# TC37XPD register map
Vendor: Infineon; Series: ATVMC; File version: 100
CPU: other r0p0, little endian, MPU, FPU, vendor SysTick, 4 interrupt priority bits
Registers are 32-bit, read-write, reset 0x0 unless marked. A register's access mark holds for its fields unless they carry their own. Offsets are from the block's base; [hi:lo] are bit positions; lines under a group give offsets from that group; {n}, {i} and the like mark numbered series.

## EDSADC
Base 0xF0024000
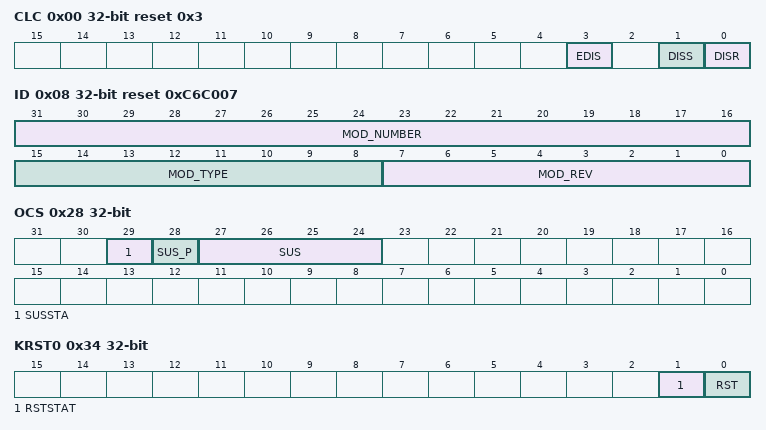
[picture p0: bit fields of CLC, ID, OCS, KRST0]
0x00 CLC access per field reset 0x3 — Clock Control Register resetvalue={Application Reset:0x3}
  [3] EDIS rw — Sleep Mode Enable Control EDIS. Used to control the module 8217 s reaction to sleep mode.
  [1] DISS ro — Module Disable Status Bit DISS
  [0] DISR rw — Module Disable Request Bit DISR. Used for enable disable control of the module.
0x08 ID ro reset 0xC6C007 — Module Identification Register resetvalue={PowerOn Reset:0x0C6C007}
  [31:16] MOD_NUMBER — Module Number MOD NUMBER. Indicates the module identification number 00C6 EDSADC
  [15:8] MOD_TYPE — Module Type MOD TYPE. This internal marker is fixed to C0 .
  [7:0] MOD_REV — Module Revision MOD REV. Indicates the revision number of the implementation. This information depends on the design step.
0x28 OCS access per field — OCDS Control and Status Register resetvalue={PowerOn Reset:0x0,Debug Reset:0x0}
  [29] SUSSTA ro — Suspend State SUSSTA
  [28] SUS_P wo — SUS Write Protection SUS P. SUS is only written when SUS P is 1 otherwise unchanged. Read as 0.
  [27:24] SUS rw — OCDS Suspend Control SUS. Controls the sensitivity to the suspend signal coming from the OCDS Trigger Switch OTGS . In soft suspend mode the respective channel is stopped after the next result has been stored. For products with less channels the upper codes are reserved.
0x2C KRSTCLR wo — Kernel Reset Status Clear Register resetvalue={Application Reset:0x0}
  [0] CLR — Kernel Reset Status Clear CLR. Read always as 0.
0x30 KRST1 — Kernel Reset Register 1 resetvalue={Application Reset:0x0}
  [0] RST — Kernel Reset RST. Request a kernel reset. The reset is executed if the reset bits of both kernel reset registers are set. RST is cleared after the kernel reset was executed.
0x34 KRST0 access per field — Kernel Reset Register 0 resetvalue={Application Reset:0x0}
  [1] RSTSTAT ro — Kernel Reset Status RSTSTAT. Indicates an executed kernel reset. RSTSTAT is set after the execution of a kernel reset in the same clock cycle in which the reset bits are cleared. Clear RSTSTAT by setting bit CLR in register KRSTCLR.
  [0] RST rw — Kernel Reset RST. Request a kernel reset. The reset is executed if the reset bits of both kernel reset registers are set. RST is cleared after the kernel reset was executed.
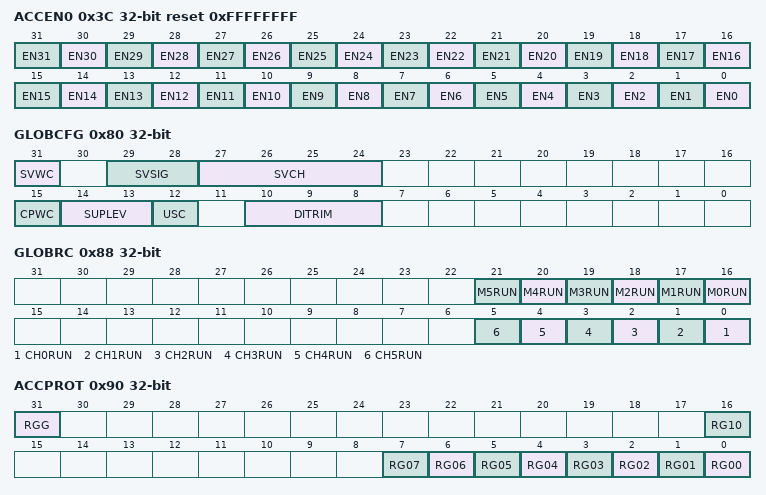
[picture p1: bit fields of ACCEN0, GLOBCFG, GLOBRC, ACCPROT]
0x3C ACCEN0 reset 0xFFFFFFFF — Access Enable Register 0 resetvalue={Application Reset:0x0FFFFFFFF}
  [n] EN{n} (n=0..31) — Access Enable for Master TAG ID 31 EN31. This bit enables write access to the module kernel addresses for transactions with the Master TAG ID n
0x80 GLOBCFG access per field — Global Configuration Register resetvalue={Application Reset:0x0}
  [31] SVWC wo — Write Control for Supervision Parameters
  [29:28] SVSIG rw — Supervision Signal Select. Defines the supervision signal of the channel selected by SVCH to be output.
  [27:24] SVCH rw — Supervision Channel Select. Defines the channel for which the supervision signal selected by SVSIG is output. Not listed combinations are reserved.
  [15] CPWC wo — Write Control for Clock Parameters CPWC
  [14:13] SUPLEV rw — Supply Voltage Level. Adjusts the analog circuitry to the supply voltage used in the application system. Make sure to keep SUPLEV 00 B or 01 B in the case of a 5 V supply.
  [12] USC rw — Unsynchronized Clock Generation USC. Defines the way the modulator clock is generated.
  [10:8] DITRIM rw — Trimming Value for the Dithering Function DITRIM. This trim value is used for all modulators of the device. Not listed combinations are reserved.
0x88 GLOBRC — Global Run Control Register resetvalue={Application Reset:0x0}
  [n+16] M{n}RUN (n=0..5) — Modulator 5 Run Control M5RUN. Each bit when set enables the corresponding modulator.
  [n] CH{n}RUN (n=0..5) — Channel 5 Run Control CH5RUN. Each bit when set enables the corresponding demodulator channel. When CHxRUN is set all filter blocks are cleared and the FIFO is flushed.
0x90 ACCPROT — Access Protection Register resetvalue={Application Reset:0x0}
  [31] RGG — Register Group Global RGG
  [16] RG10 — Register Group 10 RG10
  [n] RG{n:02} (n=0..7) — Register Group 7 RG07
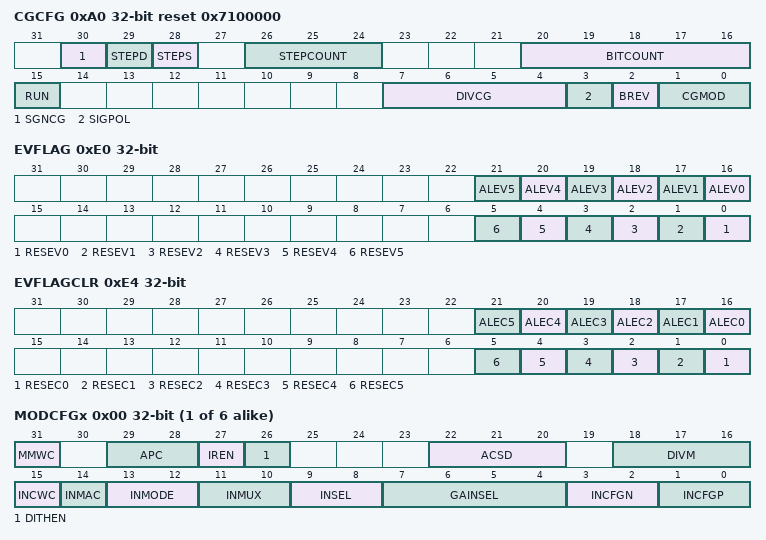
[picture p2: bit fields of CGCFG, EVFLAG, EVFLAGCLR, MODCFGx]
0xA0 CGCFG access per field reset 0x7100000 — Carrier Generator Configuration Register resetvalue={Application Reset:0x7100000}
  [30] SGNCG ro — Sign Signal from Carrier Generator SGNCG
  [29] STEPD ro — Step Counter Direction STEPD
  [28] STEPS ro — Step Counter Sign STEPS. Indicates the sign of the step counter value
  [26:24] STEPCOUNT ro — Step Counter STEPCOUNT. Counts the 8 steps generated for each quadrant of the carrier signal period
  [20:16] BITCOUNT ro — Bit Counter BITCOUNT. Counts the 32 cycles generated for each step
  [15] RUN ro — Run Indicator RUN
  [7:4] DIVCG rw — Divider Factor for the PWM Pattern Signal Generator DIVCG. Defines the input frequency of the carrier signal generator derived from the selected internal clock source f CG f ADC CGP. The frequency of the carrier signal itself is f CG 1024.
  [3] SIGPOL rw — Signal Polarity SIGPOL
  [2] BREV rw — Bit Reverse PWM Generation BREV
  [1:0] CGMOD rw — Carrier Generator Operating Mode CGMOD. Stopping the carrier generator CGMOD 160 160 00 terminates the PWM output after completion of the current period indicated by bit RUN 160 160 0 .
0xE0 EVFLAG — Event Flag Register resetvalue={Application Reset:0x0}
  [n+16] ALEV{n} (n=0..5) — Alarm Event ALEV5
  [n] RESEV{n} (n=0..5) — Result Event RESEV5. Bit RESEVx is cleared when result register RESMx is read or when bit RESECx is written with 1.
0xE4 EVFLAGCLR wo — Event Flag Clear Register resetvalue={Application Reset:0x0}
  [n+16] ALEC{n} (n=0..5) — Alarm Event Clear ALEC5
  [n] RESEC{n} (n=0..5) — Result Event Clear RESEC5
{0x100+0x100*i} CH[{i}] (i=0..5) group
  0x00 MODCFGx access per field — Modulator Configuration Register 0 resetvalue={Application Reset:0x0}
    [31] MMWC wo — Write Control for Modulator Mode Settings MMWC
    [29:28] APC rw — Automatic Power Control APC
    [27] IREN rw — Integrator Reset Enable IREN. Controls the modulator overdrive handling
    [26] DITHEN rw — Dithering Function Enable DITHEN. Controls the dithering function for each modulator separately.
    [22:20] ACSD rw — Analog Clock Synchronization Delay ACSD. Defines the delay in clocks after the sync signal. Valid only if the phase synchronizer is selected USC 160 160 0 .
    [18:16] DIVM rw — Modulator Clock Period DIVM. Defines the period of the modulator clock on chip external derived from the peripheral clock t MOD t ADC xd7 CP f MOD f ADC CP with CP 4 DIVM xd7 2.
    [15] INCWC wo — Write Control for Input Parameters INCWC
    [14] INMAC rw — Input Multiplexer Action Control INMAC. Defines the mechanism by which the input multiplexer is controlled.
    [13:12] INMODE rw — Input Multiplexer Control Mode INMODE. Defines the condition for a trigger event to control the input multiplexer. Bitfield INMAC selects the action upon a trigger event.
    [11:10] INMUX ro — Input Multiplexer Setting INMUX. Indicates the current setting of the input multiplexer connecting the input pins to the buffer inputs. The product specific appendix details the available channels and their inputs.
    [9:8] INSEL rw — Input Pin Selection INSEL. Defines the initial or permanent setting for the input multiplexer bitfield INMUX depending on the selected operating mode bitfield INMODE .
    [7:4] GAINSEL rw — Gain Select of Analog Input Path GAINSEL. Not listed combinations are reserved.
    [3:2] INCFGN rw — Configuration of Negative Input Line INCFGN. Defines the internal connection of the negative input.
    [1:0] INCFGP rw — Configuration of Positive Input Line INCFGP. Defines the internal connection of the positive input.
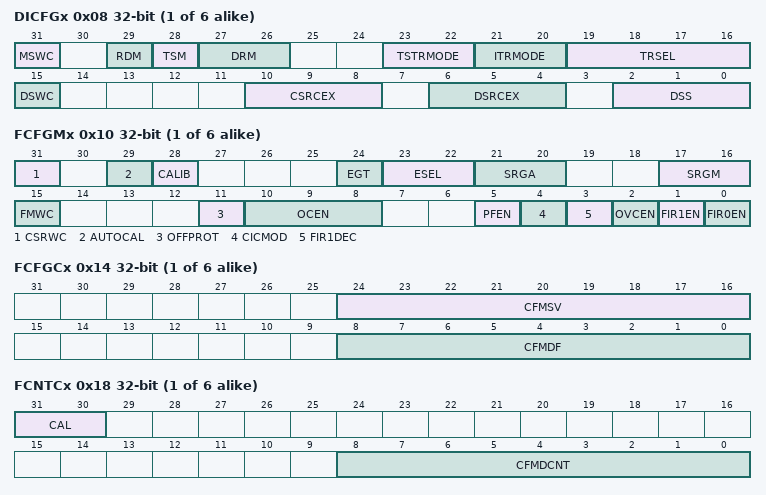
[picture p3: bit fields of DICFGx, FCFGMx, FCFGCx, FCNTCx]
  0x08 DICFGx access per field — Demodulator Input Config. Register 0 resetvalue={Application Reset:0x0}
    [31] MSWC wo — Write Control for Mode Settings MSWC
    [29] RDM rw — Result Display Mode RDM
    [28] TSM rw — Time Stamp Mode TSM. See CROSSREFERENCE .
    [27:26] DRM rw — Data Read Mode DRM. Selects the data that is returned when register RESMx is read see CROSSREFERENCE .
    [23:22] TSTRMODE rw — Timestamp Trigger Mode TSTRMODE. The timestamp trigger mode controls capturing the timestamp information to register TSTMPx .
    [21:20] ITRMODE rw — Integrator Trigger Mode ITRMODE. To ensure proper operation ensure that bitfield ITRMODE is 00 before selecting any other trigger mode. The integration trigger mode controls bit INTEN in register IWCTRx and hence the operation of the integrator Bit INTEN is set when ITRMODE 160 160 11 or when the selected trigger signal transition occurs. Bit INTEN is cleared when ITRMODE 160 160 00 after REPVAL 1 integration cycles IWS 160 160 0 or when the inverse trigger signal transition occurs IWS 160 160 1 .
    [19:16] TRSEL rw — Trigger Select TRSEL. Selects an input for the trigger signal used for the following features see also CROSSREFERENCE To avoid unintended triggers select the trigger source first before enabling the corresponding function. integrator control timestamp multiplexer control modulator control APC service request gating. The product specific appendix details the connected trigger input signals.
    [15] DSWC wo — Write Control for Data Stream Selection DSWC
    [10:8] CSRCEX rw — Clock Source for External Modulator CSRCEX
    [6:4] DSRCEX rw — Data Source for External Modulator DSRCEX
    [2:0] DSS rw — Data Stream Select DSS
  0x10 FCFGMx access per field — Filter Configuration Register 0 Main resetvalue={Application Reset:0x0}
    [31] CSRWC wo — Write Control for Calibration and Service Request Modes CSRWC
    [29] AUTOCAL rw — Automatic Calibration Control AUTOCAL
    [28] CALIB wo — Calibration Trigger CALIB
    [24] EGT rw — Event Gating. Defines if alarm events are coupled to the integration window.
    [23:22] ESEL rw — Event Select ESEL. Defines when a comparator event is generated.
    [21:20] SRGA rw — Service Request Generation for Alternate Service Request SRGA. SRGA 160 160 00 can be used for testing If TEST.ICTEN 160 160 1 Reload request for test shift register
    [17:16] SRGM rw — Service Request Generation for Main Service Request SRGM
    [15] FMWC wo — Write Control for Filter Modes FMWC
    [11] OFFPROT rw — Offset Protection OFFPROT. Controls the influence of the calibration sequence on register OFFCOMP.
    [10:8] OCEN rw — Offset Compensation Filter Enable OCEN
    [5] PFEN rw — Prefilter Enable PFEN
    [4] CICMOD rw — CIC Filter Mode CICMOD
    [3] FIR1DEC rw — FIR1 Filter Decimation Rate FIR1DEC
    [2] OVCEN rw — Overshoot Compensation Enable
    [1] FIR1EN rw — FIR1 Filter Enable FIR1EN
    [0] FIR0EN rw — FIR0 Filter Enable FIR0EN
  0x14 FCFGCx — Filter Configuration Register 0 CIC Filter resetvalue={Application Reset:0x0}
    [24:16] CFMSV — CIC Filter Start Value CFMSV. The decimation counter begins counting at value CFMSV when started or restarted. Valid values are 003 to CFMDF 4 to selected OSR . Start values above the selected oversampling rate may lead to overflows in the CIC filter
    [8:0] CFMDF — CIC Filter Decimation Factor CFMDF. Defines the oversampling rate of the CIC filter OSR CFMDF 160 160 1. Valid values are 0 03 to 1FF OSR 4 to 512 .
  0x18 FCNTCx ro — Filter Counter Register 0 CIC Filter resetvalue={Application Reset:0x0}
    [31:30] CAL — Calibration Status Flag CAL. Bitfield CAL is set to 01 in the next clock cycle after setting bit CALIB or after detecting the selected trigger if auto calibration is activated .
    [8:0] CFMDCNT — CIC Filter Decimation Counter CFMDCNT. The decimation counter counts the filter cycles until an output is generated i.e. the oversampling rate. CFMDCNT counts down from the respective start value.
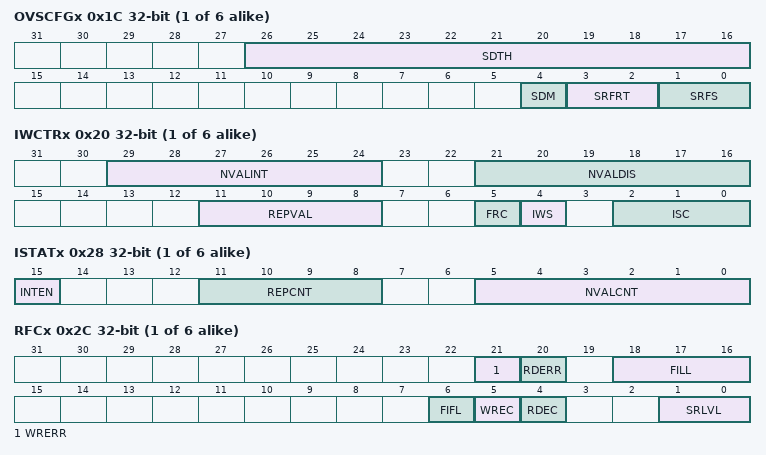
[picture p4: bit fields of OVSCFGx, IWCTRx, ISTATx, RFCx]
  0x1C OVSCFGx — Overshoot Compensation Cfg. Register 0 resetvalue={Application Reset:0x0}
    [26:16] SDTH — Step Detection Threshold. Defines the threshold value magnitude used for step detection. The threshold value is lt SDTH gt 215 32
    [4] SDM — Step Detection Mode. Defines when the slew rate filter is activated.
    [3:2] SRFRT — Slew Rate Filter Run Time. Defines the time constant for the slew rate filter.
    [1:0] SRFS — Slew Rate Filter Strength. Defines the time constant for the slew rate filter.
  0x20 IWCTRx — Integration Window Control Register 0 resetvalue={Application Reset:0x0}
    [29:24] NVALINT — Number of Values to be Accumulated NVALINT. Stop the integration cycle after NVALINT 1 values Use intervals of 2 minimum so no data is lost due to the data shifter.
    [21:16] NVALDIS — Number of Values Discarded NVALDIS. Start the integration cycle after NVALDIS values
    [11:8] REPVAL — Number of Integration Cycles REPVAL. Defines the number of integration cycles to be counted by REPCNT if activated IWS 160 160 0 . The number of cycles is REPVAL 1.
    [5] FRC — Filter Chain Restart Control
    [4] IWS — Integration Window Size IWS
    [2:0] ISC — Integrator Shift Control ISC. Controls the data shifter after the integrator that selects the portion of the integrator data for the result register. 110 8230 111 are reserved. ISC selects the respective bits in register IIVAL. The lowest selected bit is used for rounding and is then removed.
  0x24 IIVALx ro — Intermediate Integration Value resetvalue={Application Reset:0x0}
    [25:0] IVAL — Result of most recent accumulation IVAL
  0x28 ISTATx ro — Integrator Status Register 0 resetvalue={Application Reset:0x0}
    [15] INTEN — Integration Enable INTEN. Indicates the activity of the integrator. For the control of bit INTEN see also bitfield ITRMODE in register DICFGx .
    [11:8] REPCNT — Integration Cycle Counter REPCNT. Counts the number of integration cycles if activated IWS 160 160 0 . This number is selected via bitfield REPVAL.
    [5:0] NVALCNT — Number of Values Counted NVALCNT. Counts the number of integrated values until integration is started NVALDIS or completed NVALINT
  0x2C RFCx access per field — Result FIFO Control Register 0 resetvalue={Application Reset:0x0}
    [21] WRERR ro — Write Error Flag
    [20] RDERR ro — Read Error Flag
    [18:16] FILL ro — FIFO Fill Level. Not listed combinations are reserved.
    [6] FIFL wo — FIFO Flush
    [5] WREC wo — Write Error Flag Clear
    [4] RDEC wo — Read Error Flag Clear
    [1:0] SRLVL rw — Service Request FIFO Level
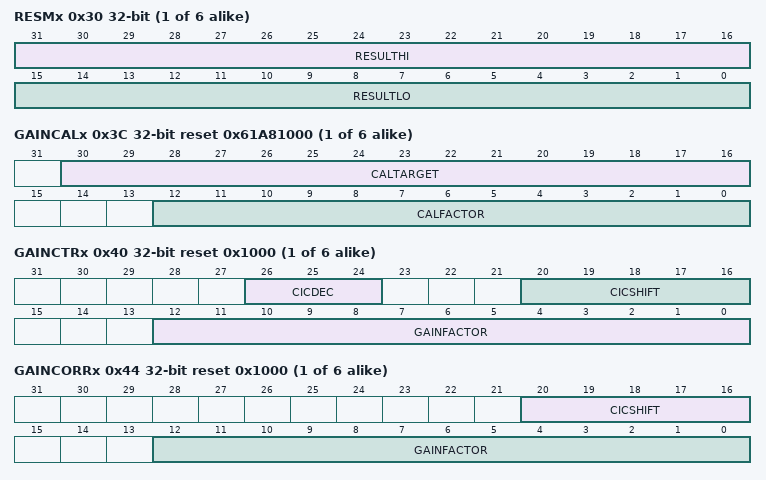
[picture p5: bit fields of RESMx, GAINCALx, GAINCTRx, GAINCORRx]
  0x30 RESMx ro — Result Register 0 Main resetvalue={Application Reset:0x0}
    [31:16] RESULTHI — Result Value Higher Part RESULTHI. Returns an additional value Sign extension result from FIFO timestamp or zero see CROSSREFERENCE
    [15:0] RESULTLO — Result Value Lower Part RESULTLO. Returns the next value from the result FIFO Result or timestamp see CROSSREFERENCE
  0x38 OFFCOMPx — Offset Compensation Register 0 resetvalue={Application Reset:0x0}
    [15:0] OFFSET — Offset Value OFFSET. Half of this signed value is subtracted from each result produced by the filter chain. Bit 0 represents 1 2 LSB. This increases the precision in case of accumulated result values e.g. in the integrator.
  0x3C GAINCALx reset 0x61A81000 — Gain Calibration Register 0 resetvalue={Application Reset:0x61A81000}
    [30:16] CALTARGET — Target Value for Calibrated Fullscale CALTARGET. Defines the target value for the calibration algorithm. The initial value of 25 160 000 61A8 corresponds to 0.2 160 mV per LSB.
    [12:0] CALFACTOR — Multiplication Factor for Gain Calibration CALFACTOR. The resulting factor is lt CALFACTOR gt 4 160 096 The initial value of 4 160 096 1000 corresponds to a factor of 1.000.
  0x40 GAINCTRx reset 0x1000 — Gain Control Register 0 resetvalue={Application Reset:0x1000}
    [26:24] CICDEC — Decimation Rate of the CIC Filter During Calibration CICDEC. Factor 2 CICDEC 3
    [20:16] CICSHIFT — Position of the CIC Filter Output Shifter During Calibration CICSHIFT. Selects the valid outputs bits from the CIC filter depending on the chosen decimation factor see data shifter formula 1D x2026 1F are reserved.
    [12:0] GAINFACTOR — Multiplication Factor for Gain Correction During Calibration GAINFACTOR. The resulting factor is lt GAINFACTOR gt 4 160 096
  0x44 GAINCORRx reset 0x1000 — Gain Correction Register 0 resetvalue={Application Reset:0x1000}
    [20:16] CICSHIFT — Position of the CIC Filter Output Shifter. Selects the valid outputs bits from the CIC filter depending on the chosen decimation factor see formula above 1D 8230 1F are reserved.
    [12:0] GAINFACTOR — Multiplication Factor for Gain Correction GAINFACTOR. The resulting factor is lt GAINFACTOR gt 4 160 096
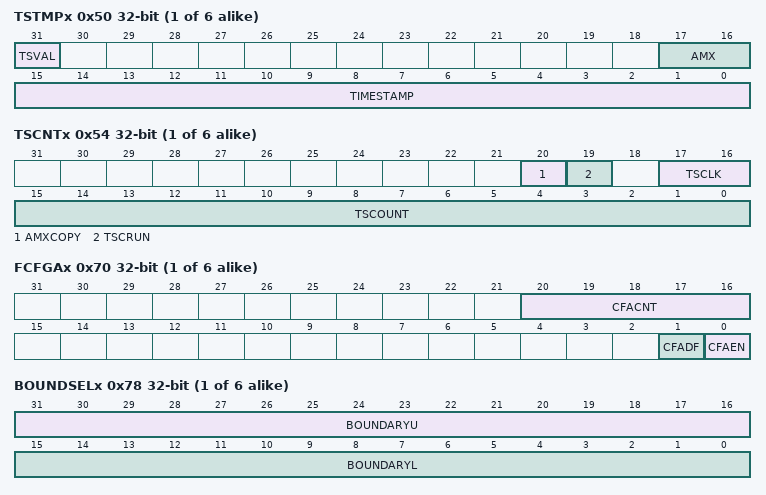
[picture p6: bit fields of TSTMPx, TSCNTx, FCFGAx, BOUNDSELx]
  0x50 TSTMPx ro — Time Stamp Register 0 resetvalue={Application Reset:0x0}
    [31] TSVAL — Timestamp Valid TSVAL. Indicates valid timestamp information.
    [17:16] AMX — Analog Multiplexer Setting AMX. This value is copied from bitfield INMUX in register MODCFGx
    [15:0] TIMESTAMP — The Most Recent Captured Timestamp Value TIMESTAMP. This value is copied from the timestamp counter TSCOUNT If bit AMXCOPY in register TSCNTx is 1 bits TIMESTAMP 15 14 are replaced with a copy of bitfield AMX.
  0x54 TSCNTx access per field — Time Stamp Counter 0 resetvalue={Application Reset:0x0}
    [20] AMXCOPY rw — Analog MUX Setting Copy Enable AMXCOPY. Allows copying of bitfield AMX into bitfield TIMESTAMP in register TSTMPx .
    [19] TSCRUN rw — Timestamp Counter Run Control TSCRUN
    [17:16] TSCLK rw — Timestamp Counter Clock Selection TSCLK
    [15:0] TSCOUNT ro — Timestamp Counter Value TSCOUNT. TSCOUNT is clocked with the modulator clock and is cleared when a new result value has been generated.
  0x70 FCFGAx access per field — Auxiliary Filter Configuration Register 0 resetvalue={Application Reset:0x0}
    [20:16] CFACNT ro — CIC Filter Auxiliary Decimation Counter. The decimation counter counts the filter cycles until an output is generated i.e. the oversampling rate.
    [1] CFADF rw — CIC Filter Auxiliary Decimation Factor
    [0] CFAEN rw — CIC Filter Auxiliary Enable
  0x78 BOUNDSELx — Boundary Select Register 0 resetvalue={Application Reset:0x0}
    [31:16] BOUNDARYU — Upper Boundary Value for Limit Checking BOUNDARYU. This two 8217 s complement value is compared to the upper bits of the CIC filter results.
    [15:0] BOUNDARYL — Lower Boundary Value for Limit Checking BOUNDARYL. This two 8217 s complement value is compared to the upper bits of the CIC filter results.
  0x80 RESAx ro — Result Register 0 Auxiliary resetvalue={Application Reset:0x0}
    [15:0] RESULT — Most Recent Result of Auxiliary Filter
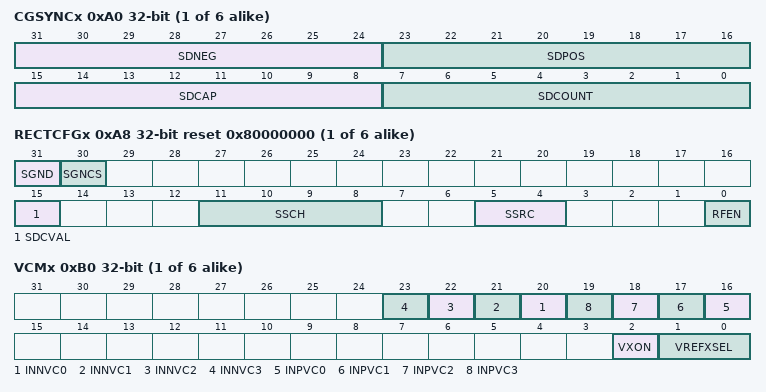
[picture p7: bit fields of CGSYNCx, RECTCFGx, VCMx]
  0xA0 CGSYNCx access per field — Carrier Generator Synchronization Reg. 0 resetvalue={Application Reset:0x0}
    [31:24] SDNEG rw — Sign Delay Value for Negative Halfwave SDNEG. Defines the content of SDCOUNT to generate a positive delayed sign signal SGND .
    [23:16] SDPOS rw — Sign Delay Value for Positive Halfwave SDPOS. Defines the content of SDCOUNT to generate a negative delayed sign signal SGND .
    [15:8] SDCAP ro — Sign Delay Capture Value SDCAP. Indicates the result values counted between the begin of the positive halfwave of the carrier signal and the first received positive value.
    [7:0] SDCOUNT ro — Sign Delay Counter SDCOUNT. Counts the result values from the filter chain to delay the carrier sign signal
  0xA8 RECTCFGx access per field reset 0x80000000 — Rectification Configuration Register 0 resetvalue={Application Reset:0x080000000}
    [31] SGND ro — Sign Signal Delayed SGND
    [30] SGNCS ro — Selected Carrier Sign Signal SGNCS
    [15] SDCVAL ro — Valid Flag SDCVAL. Indicates a new value in bitfield SDCAP.
    [11:8] SSCH rw — Sign Source Channel. Selects the channel providing the sign signal if SSRC 01 . Other products of the family may have less channels and consequently less valid SSCH codes. Not listed combinations are reserved.
    [5:4] SSRC rw — Sign Source. Selects the sign signal that is to be delayed.
    [0] RFEN rw — Rectification Enable RFEN. General control of the rectifier circuit. Rectification is only active while the integrator is active.
  0xB0 VCMx — Common Mode Voltage Register 0 resetvalue={Application Reset:0x0}
    [n+20] INNVC{n} (n=0..3) — Voltage Control of Negative Inputs 3 of CH0. Defines the connection of the respective negative input y to the common mode voltage. y indicates the input of the analog multiplexers if available .
    [n+16] INPVC{n} (n=0..3) — Voltage Control of Positive Inputs 3 of CH0. Defines the connection of the respective positive input y to the common mode voltage. y indicates the input of the analog multiplexers if available .
    [2] VXON — Fractional Reference Voltage Enable VXON
    [1:0] VREFXSEL — Fractional Reference Voltage Selection VREFXSEL
